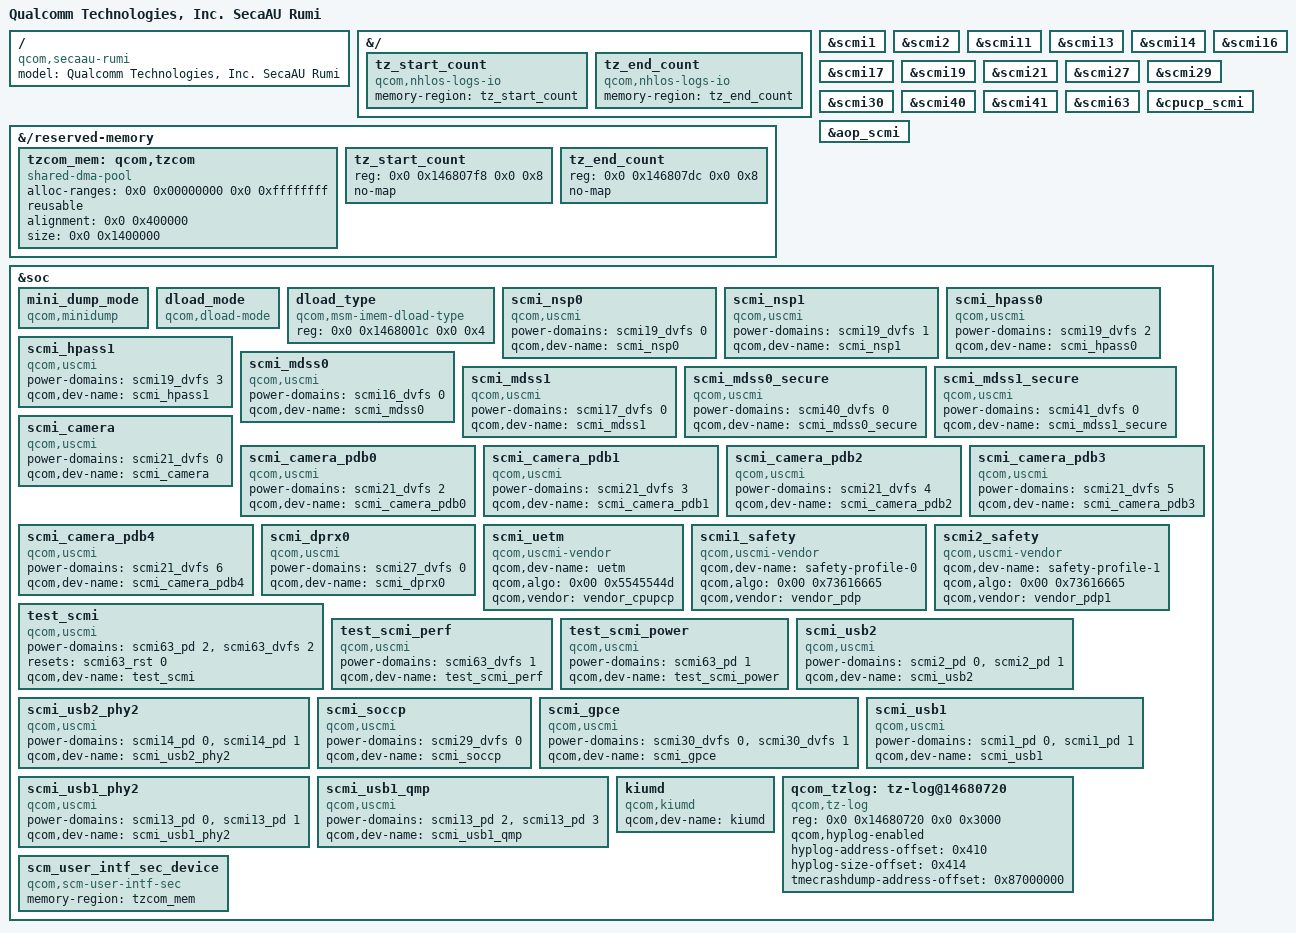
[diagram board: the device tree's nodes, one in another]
// SPDX-License-Identifier: BSD-3-Clause
/*
 * Copyright (c) Qualcomm Technologies, Inc. and/or its subsidiaries.
 */

/dts-v1/;
/plugin/;

#include <dt-bindings/interrupt-controller/arm-gic.h>
#include "seca-dma-heaps.dtsi"
#include "oot-dt-bindings/qcom-ipcc-sa8797p.h"
#include "seca-vfio.dtsi"

/ {
	model = "Qualcomm Technologies, Inc. SecaAU Rumi";
	compatible = "qcom,secaau-rumi", "qcom,seca";
};

&{/} {
	tz_start_count {
		compatible = "qcom,nhlos-logs-io", "qcom,nhlos-logs";
		memory-region = <&tz_start_count>;
	};

	tz_end_count {
		compatible = "qcom,nhlos-logs-io", "qcom,nhlos-logs";
		memory-region = <&tz_end_count>;
	};
};

&{/reserved-memory} {
	tzcom_mem: qcom,tzcom {
		compatible = "shared-dma-pool";
		alloc-ranges = <0x0 0x00000000 0x0 0xffffffff>;
		reusable;
		alignment = <0x0 0x400000>;
		size = <0x0 0x1400000>; /* 20M */
	};

	tz_start_count: tz_start_count {
		reg = <0x0 0x146807f8 0x0 0x8>;
		no-map;
	};

	tz_end_count: tz_end_count {
		reg = <0x0 0x146807dc 0x0 0x8>;
		no-map;
	};
};

&scmi1 {
	status = "okay";
};

&scmi2 {
	status = "okay";
};

&scmi11 {
	status = "okay";
};

&scmi13 {
	status = "okay";
};

&scmi14 {
	status = "okay";
};

&scmi16 {
	status = "okay";
};

&scmi17 {
	status = "okay";
};

&scmi19 {
	status = "okay";
};

&scmi21 {
	status = "okay";
};

&scmi27 {
	status = "okay";
};

&scmi29 {
	status = "okay";
};

&scmi30 {
	status = "okay";
};

&scmi40 {
	status = "okay";
};

&scmi41 {
	status = "okay";
};

&scmi63 {
	status = "okay";
};

&cpucp_scmi {
	status = "okay";
};

&aop_scmi {
	status = "okay";
};

&soc {
	mini_dump_mode {
		compatible = "qcom,minidump";
	};

	dload_mode {
		compatible = "qcom,dload-mode";
	};

	dload_type {
		compatible = "qcom,msm-imem-dload-type";
		reg = <0x0 0x1468001c 0x0 0x4>;
	};

	scmi_nsp0 {
		compatible = "qcom,uscmi";

		power-domains = <&scmi19_dvfs 0>;
		power-domain-names = "perf";

		qcom,dev-name = "scmi_nsp0";
	};

	scmi_nsp1 {
		compatible = "qcom,uscmi";

		power-domains = <&scmi19_dvfs 1>;
		power-domain-names = "perf";

		qcom,dev-name = "scmi_nsp1";
	};

	scmi_hpass0 {
		compatible = "qcom,uscmi";

		power-domains = <&scmi19_dvfs 2>;
		power-domain-names = "perf";

		qcom,dev-name = "scmi_hpass0";
	};

	scmi_hpass1 {
		compatible = "qcom,uscmi";

		power-domains = <&scmi19_dvfs 3>;
		power-domain-names = "perf";

		qcom,dev-name = "scmi_hpass1";
	};

	scmi_mdss0 {
		compatible = "qcom,uscmi";

		power-domains = <&scmi16_dvfs 0>;
		power-domain-names = "perf";

		qcom,dev-name = "scmi_mdss0";
	};

	scmi_mdss1 {
		compatible = "qcom,uscmi";

		power-domains = <&scmi17_dvfs 0>;
		power-domain-names = "perf";

		qcom,dev-name = "scmi_mdss1";
	};

	scmi_mdss0_secure {
		compatible = "qcom,uscmi";

		power-domains = <&scmi40_dvfs 0>;
		power-domain-names = "perf";

		qcom,dev-name = "scmi_mdss0_secure";
	};

	scmi_mdss1_secure {
		compatible = "qcom,uscmi";

		power-domains = <&scmi41_dvfs 0>;
		power-domain-names = "perf";

		qcom,dev-name = "scmi_mdss1_secure";
	};

	scmi_camera {
		compatible = "qcom,uscmi";

		power-domains = <&scmi21_dvfs 0>;
		power-domain-names = "perf_camera";

		qcom,dev-name = "scmi_camera";
	};

	scmi_camera_pdb0 {
		compatible = "qcom,uscmi";

		power-domains = <&scmi21_dvfs 2>;
		power-domain-names = "perf_camera_config_gpio_0";

		qcom,dev-name = "scmi_camera_pdb0";
	};

	scmi_camera_pdb1 {
		compatible = "qcom,uscmi";

		power-domains = <&scmi21_dvfs 3>;
		power-domain-names = "perf_camera_config_gpio_1";

		qcom,dev-name = "scmi_camera_pdb1";
	};

	scmi_camera_pdb2 {
		compatible = "qcom,uscmi";

		power-domains = <&scmi21_dvfs 4>;
		power-domain-names = "perf_camera_config_gpio_2";

		qcom,dev-name = "scmi_camera_pdb2";
	};

	scmi_camera_pdb3 {
		compatible = "qcom,uscmi";

		power-domains = <&scmi21_dvfs 5>;
		power-domain-names = "perf_camera_config_gpio_3";

		qcom,dev-name = "scmi_camera_pdb3";
	};

	scmi_camera_pdb4 {
		compatible = "qcom,uscmi";

		power-domains = <&scmi21_dvfs 6>;
		power-domain-names = "perf_camera_config_gpio_4";

		qcom,dev-name = "scmi_camera_pdb4";
	};

	scmi_dprx0 {
		compatible = "qcom,uscmi";

		power-domains = <&scmi27_dvfs 0>;
		power-domain-names = "perf";

		qcom,dev-name = "scmi_dprx0";
	};

	scmi_uetm {
		qcom,dev-name = "uetm";
		compatible = "qcom,uscmi-vendor";
		qcom,algo = <0x00 0x5545544d>;
		qcom,vendor = <&vendor_cpupcp>;
	};

	scmi1_safety {
		qcom,dev-name = "safety-profile-0";
		compatible = "qcom,uscmi-vendor";
		qcom,algo = <0x00 0x73616665>;
		qcom,vendor = <&vendor_pdp>;
	};

	scmi2_safety {
		qcom,dev-name = "safety-profile-1";
		compatible = "qcom,uscmi-vendor";
		qcom,algo = <0x00 0x73616665>;
		qcom,vendor = <&vendor_pdp1>;
	};

	test_scmi {
                compatible = "qcom,uscmi";

                power-domains = <&scmi63_pd 2> , <&scmi63_dvfs 2>;
                power-domain-names = "power", "perf";

                resets = <&scmi63_rst 0>;
                reset-names = "core";

                qcom,dev-name = "test_scmi";
        };

        test_scmi_perf {
                compatible = "qcom,uscmi";

                power-domains = <&scmi63_dvfs 1>;
                power-domain-names = "perf";

                qcom,dev-name = "test_scmi_perf";
        };

        test_scmi_power {
                compatible = "qcom,uscmi";

                power-domains = <&scmi63_pd 1>;

                qcom,dev-name = "test_scmi_power";
        };

	scmi_usb2 {
		compatible = "qcom,uscmi";

		power-domains = <&scmi2_pd 0>, <&scmi2_pd 1>;
		power-domain-names = "usb_transfer", "usb_core";

		qcom,dev-name = "scmi_usb2";
	};

	scmi_usb2_phy2 {
		compatible = "qcom,uscmi";

		power-domains = <&scmi14_pd 0>, <&scmi14_pd 1>;
		power-domain-names = "usb_transfer", "usb_core";

		qcom,dev-name = "scmi_usb2_phy2";
	};

	scmi_soccp {
		compatible = "qcom,uscmi";

		power-domains = <&scmi29_dvfs 0>;
		power-domain-names = "perf";

		qcom,dev-name = "scmi_soccp";
	};

	scmi_gpce {
		compatible = "qcom,uscmi";

		power-domains = <&scmi30_dvfs 0>, <&scmi30_dvfs 1>;
		power-domain-names = "gpce_core0", "gpce_core1";

		qcom,dev-name = "scmi_gpce";
	};

	scmi_usb1 {
		compatible = "qcom,uscmi";
		power-domains = <&scmi1_pd 0>, <&scmi1_pd 1>;
		power-domain-names = "usb_transfer", "usb_core";

		qcom,dev-name = "scmi_usb1";
	};

	scmi_usb1_phy2 {
		compatible = "qcom,uscmi";
		power-domains = <&scmi13_pd 0>, <&scmi13_pd 1>;
		power-domain-names = "usb_transfer", "usb_core";

		qcom,dev-name = "scmi_usb1_phy2";
	};

	scmi_usb1_qmp {
		compatible = "qcom,uscmi";
		power-domains = <&scmi13_pd 2>, <&scmi13_pd 3>;
		power-domain-names = "usb_transfer", "usb_core";

		qcom,dev-name = "scmi_usb1_qmp";
	};

	kiumd {
		compatible = "qcom,kiumd";
		qcom,dev-name = "kiumd";
		status = "ok";
	};

	qcom_tzlog: tz-log@14680720 {
		compatible = "qcom,tz-log";
		reg = <0x0 0x14680720 0x0 0x3000>;
		qcom,hyplog-enabled;
		hyplog-address-offset = <0x410>;
		hyplog-size-offset = <0x414>;
		tmecrashdump-address-offset = <0x87000000>;
	};

	scm_user_intf_sec_device {
		compatible = "qcom,scm-user-intf-sec";
		memory-region = <&tzcom_mem>;
		status = "ok";
	};
};
